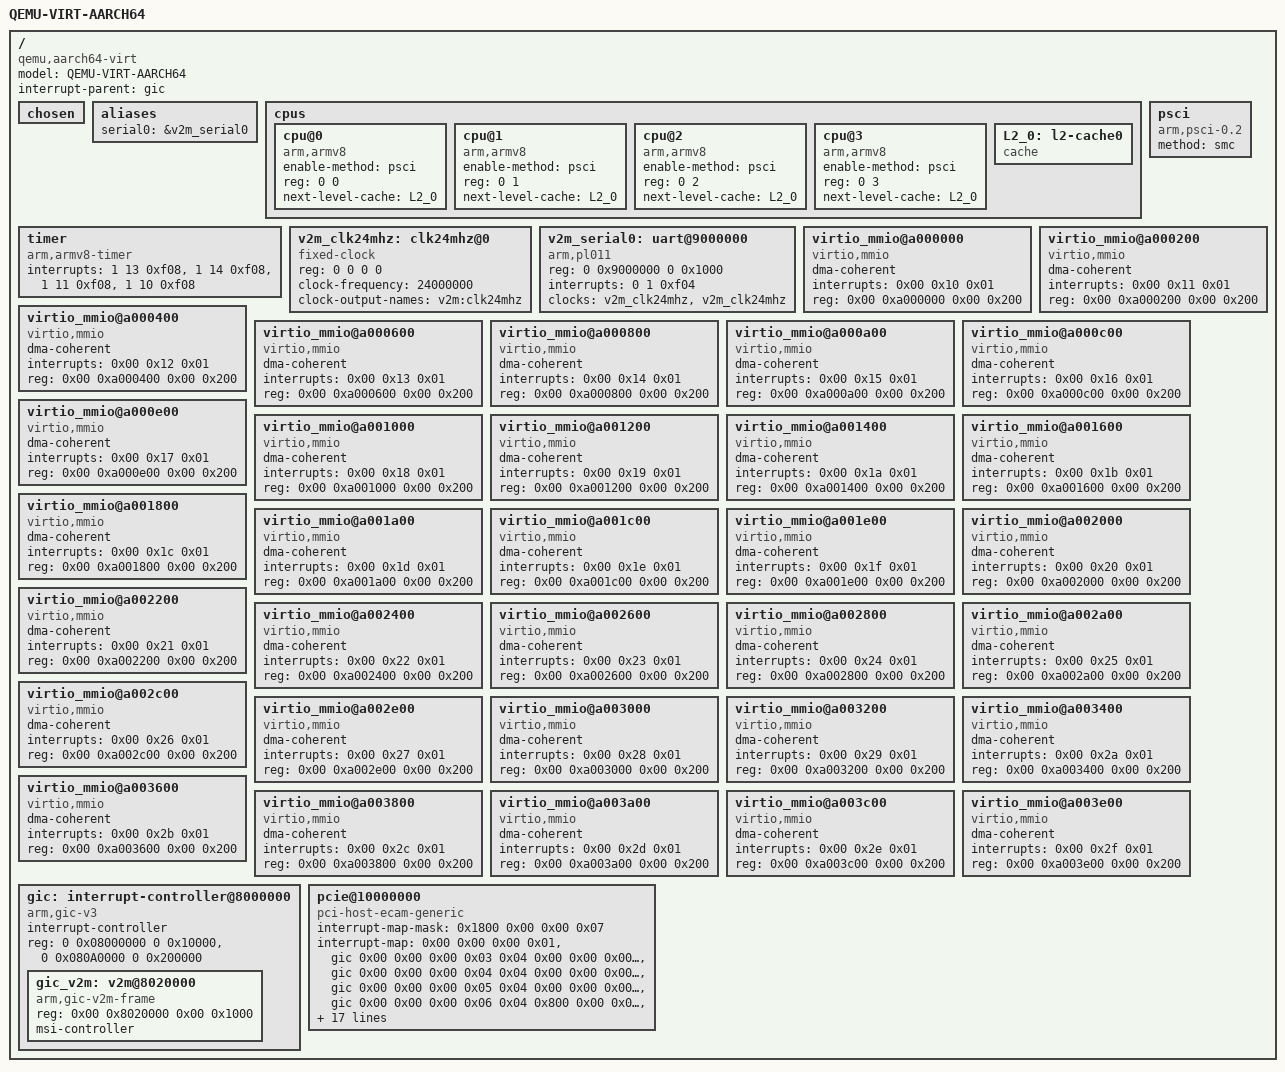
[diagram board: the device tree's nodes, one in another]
/*
 * SPDX-License-Identifier: Apache-2.0
 * Copyright (c) 2019 KapaXL (kapa.xl@outlook.com)
 *
 * QEMU-Virt-AArch64 (cortex-a35/cortex-a53/cortex-a55/
 * cortex-a57/cortex-a72/cortex-a76/cortex-a710/
 * neoverse-n1/neoverse-v1/neoverse-n2) x 4
 */

/dts-v1/;

#include "memory.dtsi"

/ {
	model = "QEMU-VIRT-AARCH64";
	compatible = "qemu,aarch64-virt";
	interrupt-parent = <&gic>;
	#address-cells = <2>;
	#size-cells = <2>;

	chosen { };

	aliases {
		serial0 = &v2m_serial0;
	};

	cpus {
		#address-cells = <2>;
		#size-cells = <0>;

		cpu@0 {
			device_type = "cpu";
			compatible = "arm,armv8";
			enable-method = "psci";
			reg = <0 0>;
			next-level-cache = <&L2_0>;
		};

		cpu@1 {
			device_type = "cpu";
			compatible = "arm,armv8";
			enable-method = "psci";
			reg = <0 1>;
			next-level-cache = <&L2_0>;
		};

		cpu@2 {
			device_type = "cpu";
			compatible = "arm,armv8";
			enable-method = "psci";
			reg = <0 2>;
			next-level-cache = <&L2_0>;
		};

		cpu@3 {
			device_type = "cpu";
			compatible = "arm,armv8";
			enable-method = "psci";
			reg = <0 3>;
			next-level-cache = <&L2_0>;
		};

		L2_0: l2-cache0 {
			compatible = "cache";
		};
	};

	psci {
		compatible = "arm,psci-0.2";
		method = "smc";
	};

	timer {
		compatible = "arm,armv8-timer";
		interrupts = <1 13 0xf08>,
				 <1 14 0xf08>,
				 <1 11 0xf08>,
				 <1 10 0xf08>;
	};

	v2m_clk24mhz: clk24mhz@0 {
		compatible = "fixed-clock";
		#clock-cells = <0>;
		reg = <0 0 0 0>;
		clock-frequency = <24000000>;
		clock-output-names = "v2m:clk24mhz";
	};

	v2m_serial0: uart@9000000 {
		compatible = "arm,pl011", "arm,primecell";
		reg = <0 0x9000000 0 0x1000>;
		interrupts = <0 1 0xf04>;
		clocks = <&v2m_clk24mhz>, <&v2m_clk24mhz>;
		clock-names = "uartclk", "apb_pclk";
	};

	virtio_mmio@a000000 {
		dma-coherent;
		interrupts = <0x00 0x10 0x01>;
		reg = <0x00 0xa000000 0x00 0x200>;
		compatible = "virtio,mmio";
	};

	virtio_mmio@a000200 {
		dma-coherent;
		interrupts = <0x00 0x11 0x01>;
		reg = <0x00 0xa000200 0x00 0x200>;
		compatible = "virtio,mmio";
	};

	virtio_mmio@a000400 {
		dma-coherent;
		interrupts = <0x00 0x12 0x01>;
		reg = <0x00 0xa000400 0x00 0x200>;
		compatible = "virtio,mmio";
	};

	virtio_mmio@a000600 {
		dma-coherent;
		interrupts = <0x00 0x13 0x01>;
		reg = <0x00 0xa000600 0x00 0x200>;
		compatible = "virtio,mmio";
	};

	virtio_mmio@a000800 {
		dma-coherent;
		interrupts = <0x00 0x14 0x01>;
		reg = <0x00 0xa000800 0x00 0x200>;
		compatible = "virtio,mmio";
	};

	virtio_mmio@a000a00 {
		dma-coherent;
		interrupts = <0x00 0x15 0x01>;
		reg = <0x00 0xa000a00 0x00 0x200>;
		compatible = "virtio,mmio";
	};

	virtio_mmio@a000c00 {
		dma-coherent;
		interrupts = <0x00 0x16 0x01>;
		reg = <0x00 0xa000c00 0x00 0x200>;
		compatible = "virtio,mmio";
	};

	virtio_mmio@a000e00 {
		dma-coherent;
		interrupts = <0x00 0x17 0x01>;
		reg = <0x00 0xa000e00 0x00 0x200>;
		compatible = "virtio,mmio";
	};

	virtio_mmio@a001000 {
		dma-coherent;
		interrupts = <0x00 0x18 0x01>;
		reg = <0x00 0xa001000 0x00 0x200>;
		compatible = "virtio,mmio";
	};

	virtio_mmio@a001200 {
		dma-coherent;
		interrupts = <0x00 0x19 0x01>;
		reg = <0x00 0xa001200 0x00 0x200>;
		compatible = "virtio,mmio";
	};

	virtio_mmio@a001400 {
		dma-coherent;
		interrupts = <0x00 0x1a 0x01>;
		reg = <0x00 0xa001400 0x00 0x200>;
		compatible = "virtio,mmio";
	};

	virtio_mmio@a001600 {
		dma-coherent;
		interrupts = <0x00 0x1b 0x01>;
		reg = <0x00 0xa001600 0x00 0x200>;
		compatible = "virtio,mmio";
	};

	virtio_mmio@a001800 {
		dma-coherent;
		interrupts = <0x00 0x1c 0x01>;
		reg = <0x00 0xa001800 0x00 0x200>;
		compatible = "virtio,mmio";
	};

	virtio_mmio@a001a00 {
		dma-coherent;
		interrupts = <0x00 0x1d 0x01>;
		reg = <0x00 0xa001a00 0x00 0x200>;
		compatible = "virtio,mmio";
	};

	virtio_mmio@a001c00 {
		dma-coherent;
		interrupts = <0x00 0x1e 0x01>;
		reg = <0x00 0xa001c00 0x00 0x200>;
		compatible = "virtio,mmio";
	};

	virtio_mmio@a001e00 {
		dma-coherent;
		interrupts = <0x00 0x1f 0x01>;
		reg = <0x00 0xa001e00 0x00 0x200>;
		compatible = "virtio,mmio";
	};

	virtio_mmio@a002000 {
		dma-coherent;
		interrupts = <0x00 0x20 0x01>;
		reg = <0x00 0xa002000 0x00 0x200>;
		compatible = "virtio,mmio";
	};

	virtio_mmio@a002200 {
		dma-coherent;
		interrupts = <0x00 0x21 0x01>;
		reg = <0x00 0xa002200 0x00 0x200>;
		compatible = "virtio,mmio";
	};

	virtio_mmio@a002400 {
		dma-coherent;
		interrupts = <0x00 0x22 0x01>;
		reg = <0x00 0xa002400 0x00 0x200>;
		compatible = "virtio,mmio";
	};

	virtio_mmio@a002600 {
		dma-coherent;
		interrupts = <0x00 0x23 0x01>;
		reg = <0x00 0xa002600 0x00 0x200>;
		compatible = "virtio,mmio";
	};

	virtio_mmio@a002800 {
		dma-coherent;
		interrupts = <0x00 0x24 0x01>;
		reg = <0x00 0xa002800 0x00 0x200>;
		compatible = "virtio,mmio";
	};

	virtio_mmio@a002a00 {
		dma-coherent;
		interrupts = <0x00 0x25 0x01>;
		reg = <0x00 0xa002a00 0x00 0x200>;
		compatible = "virtio,mmio";
	};

	virtio_mmio@a002c00 {
		dma-coherent;
		interrupts = <0x00 0x26 0x01>;
		reg = <0x00 0xa002c00 0x00 0x200>;
		compatible = "virtio,mmio";
	};

	virtio_mmio@a002e00 {
		dma-coherent;
		interrupts = <0x00 0x27 0x01>;
		reg = <0x00 0xa002e00 0x00 0x200>;
		compatible = "virtio,mmio";
	};

	virtio_mmio@a003000 {
		dma-coherent;
		interrupts = <0x00 0x28 0x01>;
		reg = <0x00 0xa003000 0x00 0x200>;
		compatible = "virtio,mmio";
	};

	virtio_mmio@a003200 {
		dma-coherent;
		interrupts = <0x00 0x29 0x01>;
		reg = <0x00 0xa003200 0x00 0x200>;
		compatible = "virtio,mmio";
	};

	virtio_mmio@a003400 {
		dma-coherent;
		interrupts = <0x00 0x2a 0x01>;
		reg = <0x00 0xa003400 0x00 0x200>;
		compatible = "virtio,mmio";
	};

	virtio_mmio@a003600 {
		dma-coherent;
		interrupts = <0x00 0x2b 0x01>;
		reg = <0x00 0xa003600 0x00 0x200>;
		compatible = "virtio,mmio";
	};

	virtio_mmio@a003800 {
		dma-coherent;
		interrupts = <0x00 0x2c 0x01>;
		reg = <0x00 0xa003800 0x00 0x200>;
		compatible = "virtio,mmio";
	};

	virtio_mmio@a003a00 {
		dma-coherent;
		interrupts = <0x00 0x2d 0x01>;
		reg = <0x00 0xa003a00 0x00 0x200>;
		compatible = "virtio,mmio";
	};

	virtio_mmio@a003c00 {
		dma-coherent;
		interrupts = <0x00 0x2e 0x01>;
		reg = <0x00 0xa003c00 0x00 0x200>;
		compatible = "virtio,mmio";
	};

	virtio_mmio@a003e00 {
		dma-coherent;
		interrupts = <0x00 0x2f 0x01>;
		reg = <0x00 0xa003e00 0x00 0x200>;
		compatible = "virtio,mmio";
	};

	gic: interrupt-controller@8000000 {
		compatible = "arm,gic-v3";
		#interrupt-cells = <3>;
		#size-cells = <0x02>;
		#address-cells = <0x02>;
		interrupt-controller;
		reg = <0 0x08000000 0 0x10000>,
			  <0 0x080A0000 0 0x200000>;
/*
 *		#address-cells = <2>;
 *		#size-cells = <2>;
 *
 *		its@8080000 {
 *				reg = <0x00 0x8080000 0x00 0x20000>;
 *				#msi-cells = <0x01>;
 *				msi-controller;
 *				compatible = "arm,gic-v3-its";
 *		};
 */
		gic_v2m: v2m@8020000 {
			reg = <0x00 0x8020000 0x00 0x1000>;
			msi-controller;
			compatible = "arm,gic-v2m-frame";
		};
	};

	pcie@10000000 {
		interrupt-map-mask = <0x1800 0x00 0x00 0x07>;
		interrupt-map = <0x00 0x00 0x00 0x01 &gic 0x00 0x00 0x00 0x03 0x04
				0x00 0x00 0x00 0x02 &gic 0x00 0x00 0x00 0x04 0x04
				0x00 0x00 0x00 0x03 &gic 0x00 0x00 0x00 0x05 0x04
				0x00 0x00 0x00 0x04 &gic 0x00 0x00 0x00 0x06 0x04
				0x800 0x00 0x00 0x01 &gic 0x00 0x00 0x00 0x04 0x04
				0x800 0x00 0x00 0x02 &gic 0x00 0x00 0x00 0x05 0x04
				0x800 0x00 0x00 0x03 &gic 0x00 0x00 0x00 0x06 0x04
				0x800 0x00 0x00 0x04 &gic 0x00 0x00 0x00 0x03 0x04
				0x1000 0x00 0x00 0x01 &gic 0x00 0x00 0x00 0x05 0x04
				0x1000 0x00 0x00 0x02 &gic 0x00 0x00 0x00 0x06 0x04
				0x1000 0x00 0x00 0x03 &gic 0x00 0x00 0x00 0x03 0x04
				0x1000 0x00 0x00 0x04 &gic 0x00 0x00 0x00 0x04 0x04
				0x1800 0x00 0x00 0x01 &gic 0x00 0x00 0x00 0x06 0x04
				0x1800 0x00 0x00 0x02 &gic 0x00 0x00 0x00 0x03 0x04
				0x1800 0x00 0x00 0x03 &gic 0x00 0x00 0x00 0x04 0x04
				0x1800 0x00 0x00 0x04 &gic 0x00 0x00 0x00 0x05 0x04>;
		#interrupt-cells = <0x01>;
		ranges = <0x1000000 0x00 0x00 0x00 0x3eff0000 0x00 0x10000
			0x2000000 0x00 0x10000000 0x00 0x10000000 0x00 0x2eff0000
			0x3000000 0x80 0x00 0x80 0x00 0x80 0x00>;
		reg = <0x40 0x10000000 0x00 0x10000000>;
		msi-map = <0x00 &gic_v2m 0x00 0x10000>;
		dma-coherent;
		bus-range = <0x00 0xff>;
		linux,pci-domain = <0x00>;
		#size-cells = <0x02>;
		#address-cells = <0x03>;
		device_type = "pci";
		compatible = "pci-host-ecam-generic";
	};
};
